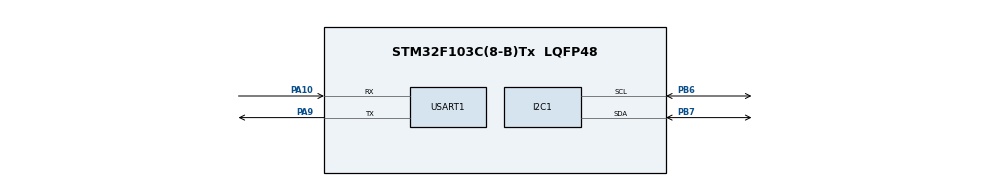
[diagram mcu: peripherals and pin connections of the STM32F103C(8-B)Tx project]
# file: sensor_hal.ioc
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Mcu.Family=STM32F1
Mcu.Name=STM32F103C(8-B)Tx
Mcu.Package=LQFP48
NVIC.PriorityGroup=NVIC_PRIORITYGROUP_4
PA10.Mode=Asynchronous
PA10.Signal=USART1_RX
PA9.Mode=Asynchronous
PA9.Signal=USART1_TX
PB6.Mode=I2C
PB6.Signal=I2C1_SCL
PB7.Mode=I2C
PB7.Signal=I2C1_SDA
ProjectManager.HeapSize=0x200
ProjectManager.StackSize=0x400
ProjectManager.TargetToolchain=Makefile
RCC.APB1Freq_Value=8000000
RCC.APB2Freq_Value=8000000
USART1.VirtualMode=VM_ASYNC
VP_SYS_VS_ND.Mode=No_Debug
board=custom

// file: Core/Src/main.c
/* USER CODE BEGIN Header */
/**
  ******************************************************************************
  * @file           : main.c
  * @brief          : Main program body
  ******************************************************************************
  * @attention
  *
  * Copyright (c) 2026 STMicroelectronics.
  * All rights reserved.
  *
  * This software is licensed under terms that can be found in the LICENSE file
  * in the root directory of this software component.
  * If no LICENSE file comes with this software, it is provided AS-IS.
  *
  ******************************************************************************
  */
/* USER CODE END Header */
#include "main.h"

/* USER CODE BEGIN Includes */
#include <stdio.h>
#include "sensor_api.h"
#include "i2c_hal.h"
#define NUM_SENSORS 2
/* USER CODE END Includes */

I2C_HandleTypeDef hi2c1;
UART_HandleTypeDef huart1;

void SystemClock_Config(void);
static void MX_GPIO_Init(void);
static void MX_I2C1_Init(void);
static void MX_USART1_UART_Init(void);
/* USER CODE BEGIN PFP */
extern i2c_bus_t stm32_create_i2c_bus(I2C_HandleTypeDef *hardware_handle);
extern void tmp108_set(SensorObject *self, i2c_bus_t *bus, uint8_t device_address);  //here we add our particular sensor
extern void adxl345_set(SensorObject *self, i2c_bus_t *bus, uint8_t device_address);
/* USER CODE END PFP */

int main(void)
{

  /* MCU Configuration--------------------------------------------------------*/

  /* Reset of all peripherals, Initializes the Flash interface and the Systick. */
  HAL_Init();

  /* Configure the system clock */
  SystemClock_Config();

  /* Initialize all configured peripherals */
  MX_GPIO_Init();
  MX_I2C1_Init();
  MX_USART1_UART_Init();
  /* USER CODE BEGIN 2 */
  printf("\nBooting Universal Sensor HAL Testing...\n");

  // --- 1. Hardware Wiring ---
  i2c_bus_t primary_i2c_bus = stm32_create_i2c_bus(&hi2c1);

  // --- 2. Sensor Instantiation ---
  SensorObject sensor_array[NUM_SENSORS];

  tmp108_set(&sensor_array[0], &primary_i2c_bus, 0x48);
  adxl345_set(&sensor_array[1], &primary_i2c_bus, 0x40);

  /* USER CODE END 2 */

  /* Infinite loop */
  /* USER CODE BEGIN WHILE */
/* Infinite loop */
  /* USER CODE BEGIN WHILE */
  while (1)
  {
    /* USER CODE END WHILE */

    // --- 3. Array Execution Sequence ---
    // This for-loop will run through all sensors, then the while(1) restarts it
    for (int i = 0; i < NUM_SENSORS; i++)
    {
        printf("\n=== Processing Sensor Index [%d] ===\n", i);

        printf("--- Step 1: Initializing Sensor ---\n");
        if (os_sensor_init(&sensor_array[i]) == 1)
        {
            printf("Success: Sensor initialized perfectly!\n");
        }
        else
        {
            printf("Error: Failed to initialize sensor.\n");
        }

        printf("--- Step 2: Reading Sensor Data ---\n");
        if (os_sensor_read(&sensor_array[i]) == 0)
        {
            printf("Error: Failed to read sensor data.\n");
        }

        printf("--- Step 3: Let sensor Sleep ---\n");
        if (os_sensor_sleep(&sensor_array[i]) == 0)
        {
            printf("API blocked: this operation is not supported by this sensor!\n");
        }

        // Optional: Short delay between reading different sensors
        HAL_Delay(50000);
    }

    printf("\nArray execution completed. Restarting from zero...\n");

    // Main delay before polling the whole array again
    HAL_Delay(3000);
  }
  /* USER CODE END 3 */
}

void SystemClock_Config(void)
{
  RCC_OscInitTypeDef RCC_OscInitStruct = {0};
  RCC_ClkInitTypeDef RCC_ClkInitStruct = {0};

  /** Initializes the RCC Oscillators according to the specified parameters
  * in the RCC_OscInitTypeDef structure.
  */
  RCC_OscInitStruct.OscillatorType = RCC_OSCILLATORTYPE_HSI;
  RCC_OscInitStruct.HSIState = RCC_HSI_ON;
  RCC_OscInitStruct.HSICalibrationValue = RCC_HSICALIBRATION_DEFAULT;
  RCC_OscInitStruct.PLL.PLLState = RCC_PLL_NONE;
  if (HAL_RCC_OscConfig(&RCC_OscInitStruct) != HAL_OK)
  {
    Error_Handler();
  }

  /** Initializes the CPU, AHB and APB buses clocks
  */
  RCC_ClkInitStruct.ClockType = RCC_CLOCKTYPE_HCLK|RCC_CLOCKTYPE_SYSCLK
                              |RCC_CLOCKTYPE_PCLK1|RCC_CLOCKTYPE_PCLK2;
  RCC_ClkInitStruct.SYSCLKSource = RCC_SYSCLKSOURCE_HSI;
  RCC_ClkInitStruct.AHBCLKDivider = RCC_SYSCLK_DIV1;
  RCC_ClkInitStruct.APB1CLKDivider = RCC_HCLK_DIV1;
  RCC_ClkInitStruct.APB2CLKDivider = RCC_HCLK_DIV1;

  if (HAL_RCC_ClockConfig(&RCC_ClkInitStruct, FLASH_LATENCY_0) != HAL_OK)
  {
    Error_Handler();
  }
}

static void MX_I2C1_Init(void)
{

  hi2c1.Instance = I2C1;
  hi2c1.Init.ClockSpeed = 100000;
  hi2c1.Init.DutyCycle = I2C_DUTYCYCLE_2;
  hi2c1.Init.OwnAddress1 = 0;
  hi2c1.Init.AddressingMode = I2C_ADDRESSINGMODE_7BIT;
  hi2c1.Init.DualAddressMode = I2C_DUALADDRESS_DISABLE;
  hi2c1.Init.OwnAddress2 = 0;
  hi2c1.Init.GeneralCallMode = I2C_GENERALCALL_DISABLE;
  hi2c1.Init.NoStretchMode = I2C_NOSTRETCH_DISABLE;
  if (HAL_I2C_Init(&hi2c1) != HAL_OK)
  {
    Error_Handler();
  }

}

static void MX_USART1_UART_Init(void)
{

  huart1.Instance = USART1;
  huart1.Init.BaudRate = 115200;
  huart1.Init.WordLength = UART_WORDLENGTH_8B;
  huart1.Init.StopBits = UART_STOPBITS_1;
  huart1.Init.Parity = UART_PARITY_NONE;
  huart1.Init.Mode = UART_MODE_TX_RX;
  huart1.Init.HwFlowCtl = UART_HWCONTROL_NONE;
  huart1.Init.OverSampling = UART_OVERSAMPLING_16;
  if (HAL_UART_Init(&huart1) != HAL_OK)
  {
    Error_Handler();
  }

}

static void MX_GPIO_Init(void)
{

  /* GPIO Ports Clock Enable */
  __HAL_RCC_GPIOA_CLK_ENABLE();
  __HAL_RCC_GPIOB_CLK_ENABLE();

}

void Error_Handler(void)
{
  __disable_irq();
  while (1)
  {
  }
}
